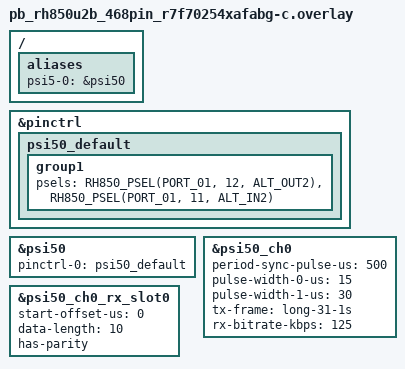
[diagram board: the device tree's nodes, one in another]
/*
 * Copyright (c) 2026 Renesas Electronics Corporation
 *
 * SPDX-License-Identifier: Apache-2.0
 */

/ {
	aliases {
		psi5-0 = &psi50;
	};
};

/*
 * PSI5 pin mux, verified against the U2Bx pin function table (pinmux-u2bx,
 * U2B10 468-pin column). Matches FSP r_psi5 pin_data.c (R7F70254x).
 *
 *   Unit   RX pin  (func)     TX pin  (func)      Ball RX/TX
 *   PSI50  P01_11  ALT_IN2    P01_12  ALT_OUT2    AH26 / AJ26
 *   PSI51  P00_2   ALT_IN2    P00_1   ALT_OUT2    AC27 / AD27
 *   PSI52  P02_9   ALT_IN2    P02_7   ALT_OUT2    AB30 / AC30
 *   PSI53  P34_0   ALT_IN1    P34_2   ALT_OUT2    C9   / C8
 *
 * Alternative PSI50 pins: P02_0 ALT_IN2 (RX, AF29) / P02_1 ALT_OUT2 (TX, AF30).
 */

&pinctrl {
	psi50_default: psi50_default {
		group1 {
			psels = <RH850_PSEL(PORT_01, 12, ALT_OUT2)>,	/* PSI50TX */
				<RH850_PSEL(PORT_01, 11, ALT_IN2)>;	/* PSI50RX */
		};
	};
};

&psi50 {
	pinctrl-0 = <&psi50_default>;
	pinctrl-names = "default";
	status = "okay";
};

&psi50_ch0 {
	period-sync-pulse-us = <500>;
	pulse-width-0-us = <15>;
	pulse-width-1-us = <30>;
	/* Long frame like the upstream NXP overlay: FRMFORMAT = 010, 16-bit TXDATA, sends 0x1234 */
	tx-frame = "long-31-1s";
	rx-bitrate-kbps = <125>;
	status = "okay";
};

&psi50_ch0_rx_slot0 {
	start-offset-us = <0>;
	data-length = <10>;
	has-parity;
	status = "okay";
};
